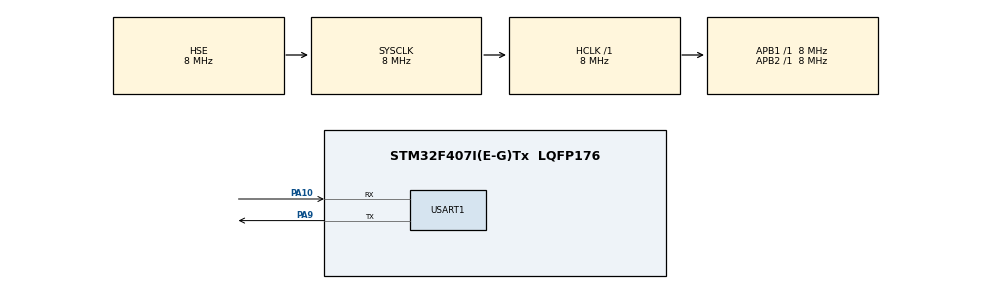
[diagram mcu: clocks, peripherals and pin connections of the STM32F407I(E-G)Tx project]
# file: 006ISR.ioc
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Mcu.Family=STM32F4
RCC.PLLSourceVirtual=RCC_PLLSOURCE_HSE
VP_SYS_VS_tim6.Mode=TIM6
PH0-OSC_IN.Signal=RCC_OSC_IN
RCC.CortexFreq_Value=8000000
PA10.Mode=Asynchronous
NVIC.TIM6_DAC_IRQn=true\:0\:0\:false\:false\:true\:false\:true
RCC.SYSCLKSource=RCC_SYSCLKSOURCE_HSE
ProjectManager.StackSize=0x400
PA9.Mode=Asynchronous
ProjectManager.TargetToolchain=STM32CubeIDE
RCC.HCLKFreq_Value=8000000
RCC.APB2TimFreq_Value=8000000
PA9.Signal=USART1_TX
RCC.LSE_VALUE=32768
RCC.AHBFreq_Value=8000000
PH0-OSC_IN.Mode=HSE-External-Oscillator
RCC.HSE_VALUE=8000000
board=custom
RCC.VCOOutputFreq_Value=96000000
RCC.APB2Freq_Value=8000000
PH1-OSC_OUT.Signal=RCC_OSC_OUT
Mcu.Name=STM32F407I(E-G)Tx
PH1-OSC_OUT.Mode=HSE-External-Oscillator
RCC.48MHZClocksFreq_Value=24000000
RCC.SYSCLKFreq_VALUE=8000000
Mcu.Package=LQFP176
NVIC.TimeBase=TIM6_DAC_IRQn
USART1.VirtualMode=VM_ASYNC
NVIC.TimeBaseIP=TIM6
PA10.Signal=USART1_RX
ProjectManager.HeapSize=0x200
RCC.HSI_VALUE=16000000
NVIC.PriorityGroup=NVIC_PRIORITYGROUP_4
RCC.APB1TimFreq_Value=8000000
RCC.APB1Freq_Value=8000000

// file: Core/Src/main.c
/* USER CODE BEGIN Header */
/**
  ******************************************************************************
  * @file           : main.c
  * @brief          : Main program body
  ******************************************************************************
  * @attention
  *
  * <h2><center>&copy; Copyright (c) 2021 STMicroelectronics.
  * All rights reserved.</center></h2>
  *
  * This software component is licensed by ST under BSD 3-Clause license,
  * the "License"; You may not use this file except in compliance with the
  * License. You may obtain a copy of the License at:
  *                        opensource.org/licenses/BSD-3-Clause
  *
  ******************************************************************************
  */
/* USER CODE END Header */
#include "main.h"

/* USER CODE BEGIN Includes */
#include <stdio.h>
#include "uart_task.h"
#include "FreeRTOS.h"
#include "task.h"
/* USER CODE END Includes */

UART_HandleTypeDef huart1;

/* USER CODE BEGIN PV */
UART_HandleTypeDef huart1;
TaskHandle_t task1_handle;
TaskHandle_t task2_handle;
TaskHandle_t task3_handle;
TaskHandle_t btn_task_handle;
TaskHandle_t volatile next_task_handle = NULL;
/* USER CODE END PV */

void SystemClock_Config(void);
static void MX_GPIO_Init(void);
static void MX_USART1_UART_Init(void);

/* USER CODE BEGIN 0 */
static void task1_handler(void* parameters);
static void task2_handler(void* parameters);
static void task3_handler(void* parameters);
void button_interrupt_handler();
void vApplicationIdleHook(void);
/* USER CODE END 0 */

int main(void)
{
  /* USER CODE BEGIN 1 */
  BaseType_t status;
  /* USER CODE END 1 */

  /* MCU Configuration--------------------------------------------------------*/

  /* Reset of all peripherals, Initializes the Flash interface and the Systick. */
  HAL_Init();

  /* Configure the system clock */
  SystemClock_Config();

  /* Initialize all configured peripherals */
  MX_GPIO_Init();
  MX_USART1_UART_Init();
  /* USER CODE BEGIN 2 */
  status = xTaskCreate(task1_handler, "Task-1", 200, "Hello world from Task-1", 2, &task1_handle);
  configASSERT(status == pdPASS);

  next_task_handle = task2_handle;

  status = xTaskCreate(task2_handler, "Task-2", 200, "Hello world from Task-2", 2, &task2_handle);
  configASSERT(status == pdPASS);

  status = xTaskCreate(task3_handler, "Task-3", 200, "Hello world from Task-3", 2, &task3_handle);
  configASSERT(status == pdPASS);

  vTaskStartScheduler();
  /* USER CODE END 2 */

  /* Infinite loop */
  while (1)
  {

  }
}

void SystemClock_Config(void)
{
  RCC_OscInitTypeDef RCC_OscInitStruct = {0};
  RCC_ClkInitTypeDef RCC_ClkInitStruct = {0};

  /** Configure the main internal regulator output voltage
  */
  __HAL_RCC_PWR_CLK_ENABLE();
  __HAL_PWR_VOLTAGESCALING_CONFIG(PWR_REGULATOR_VOLTAGE_SCALE1);
  /** Initializes the RCC Oscillators according to the specified parameters
  * in the RCC_OscInitTypeDef structure.
  */
  RCC_OscInitStruct.OscillatorType = RCC_OSCILLATORTYPE_HSE;
  RCC_OscInitStruct.HSEState = RCC_HSE_ON;
  RCC_OscInitStruct.PLL.PLLState = RCC_PLL_NONE;
  if (HAL_RCC_OscConfig(&RCC_OscInitStruct) != HAL_OK)
  {
    Error_Handler();
  }
  /** Initializes the CPU, AHB and APB buses clocks
  */
  RCC_ClkInitStruct.ClockType = RCC_CLOCKTYPE_HCLK|RCC_CLOCKTYPE_SYSCLK
                              |RCC_CLOCKTYPE_PCLK1|RCC_CLOCKTYPE_PCLK2;
  RCC_ClkInitStruct.SYSCLKSource = RCC_SYSCLKSOURCE_HSE;
  RCC_ClkInitStruct.AHBCLKDivider = RCC_SYSCLK_DIV1;
  RCC_ClkInitStruct.APB1CLKDivider = RCC_HCLK_DIV1;
  RCC_ClkInitStruct.APB2CLKDivider = RCC_HCLK_DIV1;

  if (HAL_RCC_ClockConfig(&RCC_ClkInitStruct, FLASH_LATENCY_0) != HAL_OK)
  {
    Error_Handler();
  }
}

static void MX_USART1_UART_Init(void)
{

  huart1.Instance = USART1;
  huart1.Init.BaudRate = 115200;
  huart1.Init.WordLength = UART_WORDLENGTH_8B;
  huart1.Init.StopBits = UART_STOPBITS_1;
  huart1.Init.Parity = UART_PARITY_NONE;
  huart1.Init.Mode = UART_MODE_TX_RX;
  huart1.Init.HwFlowCtl = UART_HWCONTROL_NONE;
  huart1.Init.OverSampling = UART_OVERSAMPLING_16;
  if (HAL_UART_Init(&huart1) != HAL_OK)
  {
    Error_Handler();
  }

}

static void MX_GPIO_Init(void)
{

  /* GPIO Ports Clock Enable */
  __HAL_RCC_GPIOH_CLK_ENABLE();
  __HAL_RCC_GPIOA_CLK_ENABLE();

}

/* USER CODE BEGIN 4 */
void vApplicationIdleHook(void) {
	HAL_PWR_EnterSLEEPMode(PWR_MAINREGULATOR_ON, PWR_SLEEPENTRY_WFI);
}

void  button_interrupt_handler() {
	//xTaskNotifyFromISR(next_task_handle, 0, eNoAction, NULL);

}

static void task1_handler(void* parameters) {
	BaseType_t status;
	while (1) {
		debugPrint(&huart1, "Task1\r\n");
		vTaskDelay(pdMS_TO_TICKS(1000));
		//status = xTaskNotifyWait(0, 0, NULL, pdMS_TO_TICKS(1000));
		//if( status == pdTRUE) {
			//disable interrupts
			//portENTER_CRITICAL();
			//next_task_handle = task2_handle;
			//portEXIT_CRITICAL();
			//vTaskDelete(NULL);
		//}
	}
}

static void task2_handler(void* parameters) {
	BaseType_t status;
	while (1) {
		debugPrint(&huart1, "Task2\r\n");
		vTaskDelay(pdMS_TO_TICKS(800));
		//status = xTaskNotifyWait(0, 0, NULL, pdMS_TO_TICKS(1000));
		//if( status == pdTRUE) {
			//disable interrupts
			//portENTER_CRITICAL();
			//next_task_handle = task3_handle;
			//portEXIT_CRITICAL();
			//vTaskDelete(NULL);
		//}
	}
}

static void task3_handler(void* parameters) {
	BaseType_t status;
	while (1) {
		debugPrint(&huart1, "Task3\r\n");
		vTaskDelay(pdMS_TO_TICKS(400));
		//status = xTaskNotifyWait(0, 0, NULL, pdMS_TO_TICKS(1000));
		//if( status == pdTRUE) {
			//disable interrupts
			//portENTER_CRITICAL();
			//next_task_handle = NULL;
			//portEXIT_CRITICAL();
			//vTaskDelete(NULL);
		//}
	}
}
/* USER CODE END 4 */

 /**
  * @brief  Period elapsed callback in non blocking mode
  * @note   This function is called  when TIM6 interrupt took place, inside
  * HAL_TIM_IRQHandler(). It makes a direct call to HAL_IncTick() to increment
  * a global variable "uwTick" used as application time base.
  * @param  htim : TIM handle
  * @retval None
  */
void HAL_TIM_PeriodElapsedCallback(TIM_HandleTypeDef *htim)
{
  if (htim->Instance == TIM6) {
    HAL_IncTick();
  }
}

void Error_Handler(void)
{
  __disable_irq();
  while (1)
  {
  }
}

/************************ (C) COPYRIGHT STMicroelectronics *****END OF FILE****/
